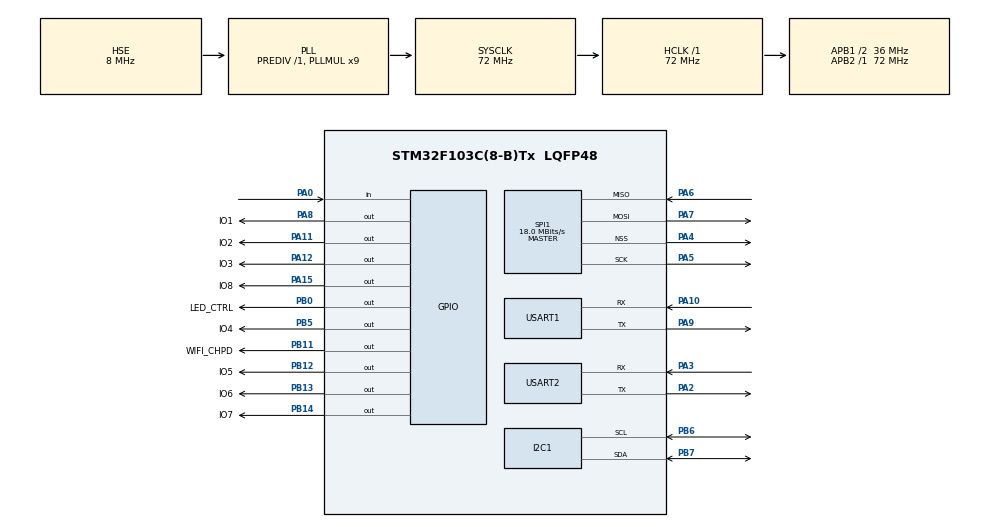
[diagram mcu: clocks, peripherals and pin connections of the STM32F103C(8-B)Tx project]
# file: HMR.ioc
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FREERTOS.Tasks01=defaultTask,0,128,StartDefaultTask,Default,NULL
Mcu.Family=STM32F1
Mcu.Name=STM32F103C(8-B)Tx
Mcu.Package=LQFP48
NVIC.PriorityGroup=NVIC_PRIORITYGROUP_4
NVIC.TIM4_IRQn=true\:0\:0\:false\:false\:true\:false\:false
NVIC.TimeBase=TIM4_IRQn
NVIC.TimeBaseIP=TIM4
PA0-WKUP.Signal=GPIO_Input
PA10.Mode=Asynchronous
PA10.Signal=USART1_RX
PA11.GPIO_Label=IO2
PA11.Signal=GPIO_Output
PA12.GPIO_Label=IO3
PA12.Signal=GPIO_Output
PA13.Mode=Serial_Wire
PA13.Signal=SYS_JTMS-SWDIO
PA14.Mode=Serial_Wire
PA14.Signal=SYS_JTCK-SWCLK
PA15.GPIO_Label=IO8
PA15.Signal=GPIO_Output
PA2.Mode=Asynchronous
PA2.Signal=USART2_TX
PA3.Mode=Asynchronous
PA3.Signal=USART2_RX
PA4.Mode=NSS_Signal_Hard_Output
PA4.Signal=SPI1_NSS
PA5.Mode=Full_Duplex_Master
PA5.Signal=SPI1_SCK
PA6.Mode=Full_Duplex_Master
PA6.Signal=SPI1_MISO
PA7.Mode=Full_Duplex_Master
PA7.Signal=SPI1_MOSI
PA8.GPIO_Label=IO1
PA8.Signal=GPIO_Output
PA9.Mode=Asynchronous
PA9.Signal=USART1_TX
PB0.GPIO_Label=LED_CTRL
PB0.Signal=GPIO_Output
PB11.GPIO_Label=WIFI_CHPD
PB11.Signal=GPIO_Output
PB12.GPIO_Label=IO5
PB12.Signal=GPIO_Output
PB13.GPIO_Label=IO6
PB13.Signal=GPIO_Output
PB14.GPIO_Label=IO7
PB14.Signal=GPIO_Output
PB5.GPIO_Label=IO4
PB5.Signal=GPIO_Output
PB6.Mode=I2C
PB6.Signal=I2C1_SCL
PB7.Mode=I2C
PB7.Signal=I2C1_SDA
PD0-OSC_IN.Mode=HSE-External-Oscillator
PD0-OSC_IN.Signal=RCC_OSC_IN
PD1-OSC_OUT.Mode=HSE-External-Oscillator
PD1-OSC_OUT.Signal=RCC_OSC_OUT
ProjectManager.HeapSize=0x200
ProjectManager.StackSize=0x400
ProjectManager.TargetToolchain=MDK-ARM V5
RCC.AHBFreq_Value=72000000
RCC.APB1CLKDivider=RCC_HCLK_DIV2
RCC.APB1Freq_Value=36000000
RCC.APB1TimFreq_Value=72000000
RCC.APB2Freq_Value=72000000
RCC.APB2TimFreq_Value=72000000
RCC.HCLKFreq_Value=72000000
RCC.PLLMUL=RCC_PLL_MUL9
RCC.PLLSourceVirtual=RCC_PLLSOURCE_HSE
RCC.SYSCLKFreq_VALUE=72000000
RCC.SYSCLKSource=RCC_SYSCLKSOURCE_PLLCLK
RCC.USBFreq_Value=72000000
SPI1.BaudRatePrescaler=SPI_BAUDRATEPRESCALER_4
SPI1.CalculateBaudRate=18.0 MBits/s
SPI1.Direction=SPI_DIRECTION_2LINES
SPI1.Mode=SPI_MODE_MASTER
SPI1.VirtualNSS=VM_NSSHARD
SPI1.VirtualType=VM_MASTER
USART1.VirtualMode=VM_ASYNC
USART2.VirtualMode=VM_ASYNC
VP_FREERTOS_VS_ENABLE.Mode=Enabled
VP_IWDG_VS_IWDG.Mode=IWDG_Activate
VP_SYS_VS_tim4.Mode=TIM4
VP_WWDG_VS_WWDG.Mode=WWDG_Activate
board=HMR

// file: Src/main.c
/**
  ******************************************************************************
  * @file           : main.c
  * @brief          : Main program body
  ******************************************************************************
  * This notice applies to any and all portions of this file
  * that are not between comment pairs USER CODE BEGIN and
  * USER CODE END. Other portions of this file, whether
  * inserted by the user or by software development tools
  * are owned by their respective copyright owners.
  *
  * Copyright (c) 2018 STMicroelectronics International N.V.
  * All rights reserved.
  *
  * Redistribution and use in source and binary forms, with or without
  * modification, are permitted, provided that the following conditions are met:
  *
  * 1. Redistribution of source code must retain the above copyright notice,
  *    this list of conditions and the following disclaimer.
  * 2. Redistributions in binary form must reproduce the above copyright notice,
  *    this list of conditions and the following disclaimer in the documentation
  *    and/or other materials provided with the distribution.
  * 3. Neither the name of STMicroelectronics nor the names of other
  *    contributors to this software may be used to endorse or promote products
  *    derived from this software without specific written permission.
  * 4. This software, including modifications and/or derivative works of this
  *    software, must execute solely and exclusively on microcontroller or
  *    microprocessor devices manufactured by or for STMicroelectronics.
  * 5. Redistribution and use of this software other than as permitted under
  *    this license is void and will automatically terminate your rights under
  *    this license.
  *
  * THIS SOFTWARE IS PROVIDED BY STMICROELECTRONICS AND CONTRIBUTORS "AS IS"
  * AND ANY EXPRESS, IMPLIED OR STATUTORY WARRANTIES, INCLUDING, BUT NOT
  * LIMITED TO, THE IMPLIED WARRANTIES OF MERCHANTABILITY, FITNESS FOR A
  * PARTICULAR PURPOSE AND NON-INFRINGEMENT OF THIRD PARTY INTELLECTUAL PROPERTY
  * RIGHTS ARE DISCLAIMED TO THE FULLEST EXTENT PERMITTED BY LAW. IN NO EVENT
  * SHALL STMICROELECTRONICS OR CONTRIBUTORS BE LIABLE FOR ANY DIRECT, INDIRECT,
  * INCIDENTAL, SPECIAL, EXEMPLARY, OR CONSEQUENTIAL DAMAGES (INCLUDING, BUT NOT
  * LIMITED TO, PROCUREMENT OF SUBSTITUTE GOODS OR SERVICES; LOSS OF USE, DATA,
  * OR PROFITS; OR BUSINESS INTERRUPTION) HOWEVER CAUSED AND ON ANY THEORY OF
  * LIABILITY, WHETHER IN CONTRACT, STRICT LIABILITY, OR TORT (INCLUDING
  * NEGLIGENCE OR OTHERWISE) ARISING IN ANY WAY OUT OF THE USE OF THIS SOFTWARE,
  * EVEN IF ADVISED OF THE POSSIBILITY OF SUCH DAMAGE.
  *
  ******************************************************************************
  */
#include "main.h"
#include "stm32f1xx_hal.h"
#include "cmsis_os.h"
#include "i2c.h"
#include "iwdg.h"
#include "spi.h"
#include "usart.h"
#include "wwdg.h"
#include "gpio.h"
#include "Signal_Generation.h"

//#include "stdint.h""

/* USER CODE BEGIN Includes */
#include "Device.h"
/* USER CODE END Includes */

/* USER CODE BEGIN PV */
/* Private variables ---------------------------------------------------------*/

/* USER CODE END PV */

void SystemClock_Config(void);
void MX_FREERTOS_Init(void);

/* USER CODE BEGIN PFP */
/* Private function prototypes -----------------------------------------------*/

/* USER CODE END PFP */

/* USER CODE BEGIN 0 */
uint8_t test_num=0;
/* USER CODE END 0 */

int main(void)
{

  /* MCU Configuration----------------------------------------------------------*/

  /* Reset of all peripherals, Initializes the Flash interface and the Systick. */
  HAL_Init();

  /* USER CODE BEGIN Init */
	//test_num=16;
  /* USER CODE END Init */

  /* Configure the system clock */
  SystemClock_Config();

  /* Initialize all configured peripherals */
#if 0

  MX_GPIO_Init();
  MX_USART2_UART_Init();
  MX_SPI1_Init();
  MX_USART1_UART_Init();
  MX_I2C1_Init();

#endif

	 MX_GPIO_Init();
   DEV_Open(DEVICE_FOUR);		//开启串口设备
	 DEV_Open(DEVICE_TWO);		//开启PWM产生设备
	 SetPWMFreq(250);					//设置PWM频率    舵机区间500us~2500us   具体设置参考该舵机属性

  // MX_USART1_UART_Init();
	// MX_USART2_UART_Init();

  /* Call init function for freertos objects (in freertos.c) */
  MX_FREERTOS_Init();

  /* Start scheduler */
  osKernelStart();

  /* We should never get here as control is now taken by the scheduler */

  /* Infinite loop */
  while (1)
  {

  }
}

void SystemClock_Config(void)
{

  RCC_OscInitTypeDef RCC_OscInitStruct;
  RCC_ClkInitTypeDef RCC_ClkInitStruct;

  /**Initializes the CPU, AHB and APB busses clocks
    */
  RCC_OscInitStruct.OscillatorType = RCC_OSCILLATORTYPE_LSI | RCC_OSCILLATORTYPE_HSE;
  RCC_OscInitStruct.HSEState = RCC_HSE_ON;
  RCC_OscInitStruct.HSEPredivValue = RCC_HSE_PREDIV_DIV1;
  RCC_OscInitStruct.HSIState = RCC_HSI_ON;
  RCC_OscInitStruct.LSIState = RCC_LSI_ON;
  RCC_OscInitStruct.PLL.PLLState = RCC_PLL_ON;
  RCC_OscInitStruct.PLL.PLLSource = RCC_PLLSOURCE_HSE;
  RCC_OscInitStruct.PLL.PLLMUL = RCC_PLL_MUL9;
  if (HAL_RCC_OscConfig(&RCC_OscInitStruct) != HAL_OK)
  {
    _Error_Handler(__FILE__, __LINE__);
  }

  /**Initializes the CPU, AHB and APB busses clocks
    */
  RCC_ClkInitStruct.ClockType = RCC_CLOCKTYPE_HCLK | RCC_CLOCKTYPE_SYSCLK | RCC_CLOCKTYPE_PCLK1 | RCC_CLOCKTYPE_PCLK2;
  RCC_ClkInitStruct.SYSCLKSource = RCC_SYSCLKSOURCE_PLLCLK;
  RCC_ClkInitStruct.AHBCLKDivider = RCC_SYSCLK_DIV1;
  RCC_ClkInitStruct.APB1CLKDivider = RCC_HCLK_DIV2;
  RCC_ClkInitStruct.APB2CLKDivider = RCC_HCLK_DIV1;

  if (HAL_RCC_ClockConfig(&RCC_ClkInitStruct, FLASH_LATENCY_2) != HAL_OK)
  {
    _Error_Handler(__FILE__, __LINE__);
  }

  /**Configure the Systick interrupt time
    */
  HAL_SYSTICK_Config(HAL_RCC_GetHCLKFreq() / 1000);

  /**Configure the Systick
    */
  HAL_SYSTICK_CLKSourceConfig(SYSTICK_CLKSOURCE_HCLK);

  /* SysTick_IRQn interrupt configuration */
  HAL_NVIC_SetPriority(SysTick_IRQn, 15, 0);
}

void HAL_TIM_PeriodElapsedCallback(TIM_HandleTypeDef *htim)
{
  if (htim->Instance == TIM4)
  {
    HAL_IncTick();
  }
}

void _Error_Handler(char *file, int line)
{
  while (1)
  {
  }
}

/************************ (C) COPYRIGHT STMicroelectronics *****END OF FILE****/

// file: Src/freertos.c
/**
  ******************************************************************************
  * File Name          : freertos.c
  * Description        : Code for freertos applications
  ******************************************************************************
  * This notice applies to any and all portions of this file
  * that are not between comment pairs USER CODE BEGIN and
  * USER CODE END. Other portions of this file, whether
  * inserted by the user or by software development tools
  * are owned by their respective copyright owners.
  *
  * Copyright (c) 2018 STMicroelectronics International N.V.
  * All rights reserved.
  *
  * Redistribution and use in source and binary forms, with or without
  * modification, are permitted, provided that the following conditions are met:
  *
  * 1. Redistribution of source code must retain the above copyright notice,
  *    this list of conditions and the following disclaimer.
  * 2. Redistributions in binary form must reproduce the above copyright notice,
  *    this list of conditions and the following disclaimer in the documentation
  *    and/or other materials provided with the distribution.
  * 3. Neither the name of STMicroelectronics nor the names of other
  *    contributors to this software may be used to endorse or promote products
  *    derived from this software without specific written permission.
  * 4. This software, including modifications and/or derivative works of this
  *    software, must execute solely and exclusively on microcontroller or
  *    microprocessor devices manufactured by or for STMicroelectronics.
  * 5. Redistribution and use of this software other than as permitted under
  *    this license is void and will automatically terminate your rights under
  *    this license.
  *
  * THIS SOFTWARE IS PROVIDED BY STMICROELECTRONICS AND CONTRIBUTORS "AS IS"
  * AND ANY EXPRESS, IMPLIED OR STATUTORY WARRANTIES, INCLUDING, BUT NOT
  * LIMITED TO, THE IMPLIED WARRANTIES OF MERCHANTABILITY, FITNESS FOR A
  * PARTICULAR PURPOSE AND NON-INFRINGEMENT OF THIRD PARTY INTELLECTUAL PROPERTY
  * RIGHTS ARE DISCLAIMED TO THE FULLEST EXTENT PERMITTED BY LAW. IN NO EVENT
  * SHALL STMICROELECTRONICS OR CONTRIBUTORS BE LIABLE FOR ANY DIRECT, INDIRECT,
  * INCIDENTAL, SPECIAL, EXEMPLARY, OR CONSEQUENTIAL DAMAGES (INCLUDING, BUT NOT
  * LIMITED TO, PROCUREMENT OF SUBSTITUTE GOODS OR SERVICES; LOSS OF USE, DATA,
  * OR PROFITS; OR BUSINESS INTERRUPTION) HOWEVER CAUSED AND ON ANY THEORY OF
  * LIABILITY, WHETHER IN CONTRACT, STRICT LIABILITY, OR TORT (INCLUDING
  * NEGLIGENCE OR OTHERWISE) ARISING IN ANY WAY OUT OF THE USE OF THIS SOFTWARE,
  * EVEN IF ADVISED OF THE POSSIBILITY OF SUCH DAMAGE.
  *
  ******************************************************************************
  */

#include "FreeRTOS.h"
#include "task.h"
#include "cmsis_os.h"

osThreadId HMR_Dispatch_TaskHandle;
osThreadId HMR_Protocol_Decode_TaskHandle;
osThreadId HMR_Action_Ctrl_TaskHandle;
osThreadId HMR_Print_TaskHandle;

extern void HMR_Dispatch(void const *argument);
extern void HMR_Protocol_Decode(void const *argument);
extern void HMR_Action_Ctrl(void const *argument);
extern void HMR_Print(void const *argument);

void MX_FREERTOS_Init(void); /* (MISRA C 2004 rule 8.1) */

/* Hook prototypes */

/* Init FreeRTOS */

void MX_FREERTOS_Init(void)
{

  /* Create the thread(s) */
  /* definition and creation of defaultTask */

//  osThreadDef(HMR_Dispatch_Task, HMR_Dispatch, osPriorityNormal, 0, 128);
//  HMR_Dispatch_TaskHandle = osThreadCreate(osThread(HMR_Dispatch_Task), NULL);

//	osThreadDef(HMR_Protocol_Decode_Task, HMR_Protocol_Decode, osPriorityNormal, 0, 128);
//  HMR_Protocol_Decode_TaskHandle = osThreadCreate(osThread(HMR_Protocol_Decode_Task), NULL);

	osThreadDef(HMR_Action_Ctrl_Task, HMR_Action_Ctrl, osPriorityRealtime, 0, 128);
  HMR_Action_Ctrl_TaskHandle = osThreadCreate(osThread(HMR_Action_Ctrl_Task), NULL);

	osThreadDef(HMR_Print_Task, HMR_Print, osPriorityNormal, 0, 128);
  HMR_Protocol_Decode_TaskHandle = osThreadCreate(osThread(HMR_Print_Task), NULL);

}

/************************ (C) COPYRIGHT STMicroelectronics *****END OF FILE****/
